VERSION ""

NS_ :

BS_:

BU_:

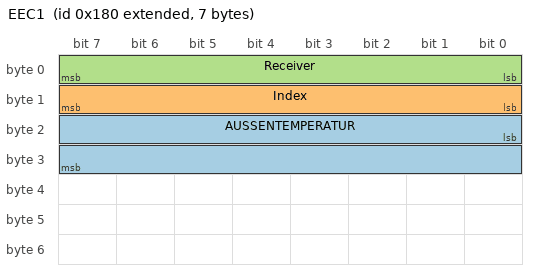
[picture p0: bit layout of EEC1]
BO_ 2147484032 EEC1: 7 Vector__XXX
	SG_ AUSSENTEMPERATUR : 16|16@1+ (0.1,0) [0|0] "Celsius" Vector__XXX
	SG_ Index : 8|8@1+ (1,0) [0|0] "" Vector__XXX
	SG_ Receiver : 0|8@1+ (1,0) [0|0] "" Vector__XXX

BO_ 2147484047 CCVS1: 7 Vector__XXX
	SG_ WheelBasedVehicleSpeed : 8|16@1+ (0.00390625,0) [0|250.996] "km/h" Vector__XXX

CM_ BO_ 2147484032 "AUSSENTEMPERATUR";
CM_ SG_ 2147484032 AUSSENTEMPERATUR "Actual engine speed which is calculated over a minimum crankshaft angle of 720 degrees divided by the number of cylinders.â€¦";
CM_ BO_ 2147484047 "Cruise Control/Vehicle Speed 1";
CM_ SG_ 2566844926 WheelBasedVehicleSpeed "Wheel-Based Vehicle Speed: Speed of the vehicle as calculated from wheel or tailshaft speed.";
BA_DEF_ SG_  "SPN" INT 0 524287;
BA_DEF_ BO_  "VFrameFormat" ENUM  "StandardCAN","ExtendedCAN","reserved","J1939PG";
BA_DEF_  "DatabaseVersion" STRING ;
BA_DEF_  "BusType" STRING ;
BA_DEF_  "ProtocolType" STRING ;
BA_DEF_  "DatabaseCompiler" STRING ;
BA_DEF_DEF_  "SPN" 0;
BA_DEF_DEF_  "VFrameFormat" "J1939PG";
BA_DEF_DEF_  "DatabaseVersion" "DEMO PLUS";
BA_DEF_DEF_  "BusType" "";
BA_DEF_DEF_  "ProtocolType" "";
BA_DEF_DEF_  "DatabaseCompiler" "";
BA_ "ProtocolType" "J1939";
BA_ "BusType" "CAN";
BA_ "DatabaseCompiler" "CSS ELECTRONICS (WWW.CSSELECTRONICS.COM)";
BA_ "DatabaseVersion" "1.0.0";
BA_ "SPN" SG_ 2364540158 EngineSpeed 190;
BA_ "SPN" SG_ 2566844926 WheelBasedVehicleSpeed 84;
